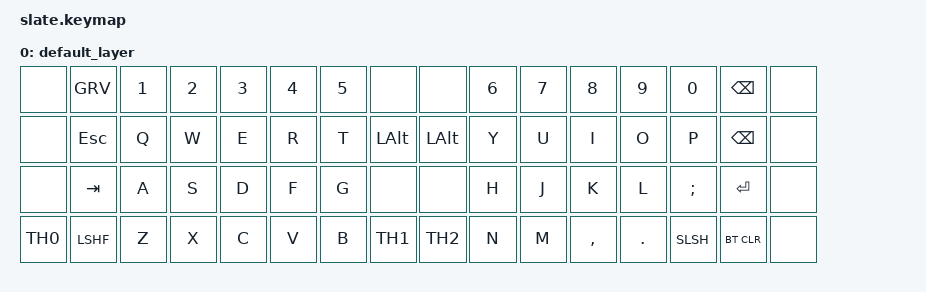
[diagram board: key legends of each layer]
#include <behaviors.dtsi>
#include <dt-bindings/zmk/keys.h>
#include <dt-bindings/zmk/bt.h>

/ {
    keymap {
        compatible = "zmk,keymap";
        label = "Km";

        default_layer {
            bindings = <
        &none    &kp GRV &kp N1  &kp N2  &kp N3  &kp N4  &kp N5  &none    &none    &kp N6  &kp N7  &kp N8  &kp N9  &kp N0  &kp BSPC &none
        &none    &kp ESC &kp Q   &kp W   &kp E   &kp R   &kp T   &kp LALT &kp LALT &kp Y   &kp U   &kp I   &kp O   &kp P   &kp BKSP &none
        &none    &kp TAB &kp A   &kp S   &kp D   &kp F   &kp G   &none    &none    &kp H   &kp J   &kp K   &kp L   &kp SCLN&kp RET  &none
        &kp TH0  &kp LSHF&kp Z   &kp X   &kp C   &kp V   &kp B   &kp TH1  &kp TH2  &kp N   &kp M   &kp COMMA&kp DOT &kp SLSH&bt BT_CLR&none
      >;
        };
    };
};

